# STM32F40x register map
File version: 1.5
Registers are 32-bit, read-write, reset 0x0 unless marked. A register's access mark holds for its fields unless they carry their own. Offsets are from the block's base; [hi:lo] are bit positions.

## TIM6（定时器6(基本定时器)） — 基本定时器：计数/比较/PWM/输入捕获 | Basic timers
Base 0x40001000
Same registers: TIM7（定时器7(基本定时器)） 0x40001400
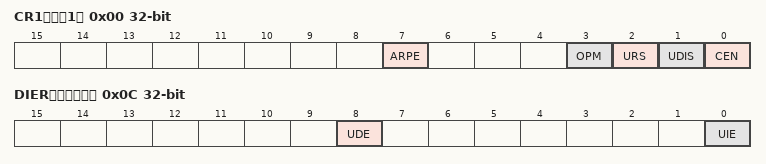
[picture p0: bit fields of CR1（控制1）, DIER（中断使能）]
0x00 CR1（控制1） — 控制1：计数器使能/对齐/分频 | control register 1
  [7] ARPE — Auto-reload preload enable
  [3] OPM — One-pulse mode
  [2] URS — Update request source
  [1] UDIS — Update disable
  [0] CEN — Counter enable
0x04 CR2（控制2） — 控制2：主模式选择 | control register 2
  [6:4] MMS — Master mode selection
0x0C DIER（中断使能） — DMA/中断使能 | DMA/Interrupt enable register
  [8] UDE — Update DMA request enable
  [0] UIE — Update interrupt enable
0x10 SR（状态） — 状态：更新中断标志 | status register
  [0] UIF — Update interrupt flag
0x14 EGR（事件生成） wo — 事件生成 | event generation register
  [0] UG — Update generation
0x24 CNT（计数器） — 当前计数值 | counter
  [15:0] CNT — Low counter value
0x28 PSC（预分频） — 预分频 | prescaler
  [15:0] PSC — Prescaler value
0x2C ARR（自动重装） — 自动重装载值 | auto-reload register
  [15:0] ARR — Low Auto-reload value

## Ethernet_MAC（以太网_MAC_媒体访问控制） — 以太网 MAC 媒体访问控制（best-effort） | Ethernet: media access control (MAC)
Base 0x40028000
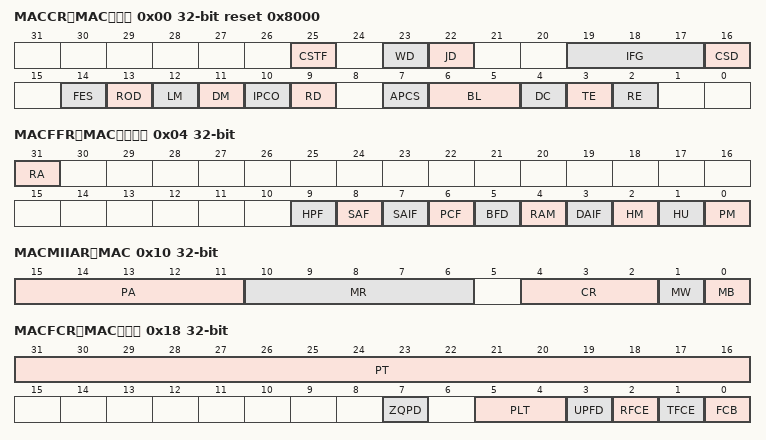
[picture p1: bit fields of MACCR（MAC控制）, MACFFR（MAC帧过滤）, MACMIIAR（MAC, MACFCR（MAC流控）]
0x00 MACCR（MAC控制） reset 0x8000 — MAC 控制 | Ethernet MAC configuration register
  [25] CSTF, [23] WD, [22] JD, [19:17] IFG, [16] CSD, [14] FES, [13] ROD, [12] LM, [11] DM, [10] IPCO, [9] RD, [7] APCS, [6:5] BL, [4] DC, [3] TE, [2] RE
0x04 MACFFR（MAC帧过滤） — MAC 帧过滤 | Ethernet MAC frame filter register
  [31] RA, [9] HPF, [8] SAF, [7] SAIF, [6] PCF, [5] BFD, [4] RAM, [3] DAIF, [2] HM, [1] HU, [0] PM
0x08 MACHTHR（MAC哈希高） — MAC 哈希表高 | Ethernet MAC hash table high register
  [31:0] HTH
0x0C MACHTLR（MAC哈希低） — MAC 哈希表低 | Ethernet MAC hash table low register
  [31:0] HTL
0x10 MACMIIAR（MAC MII地址） — MAC MII 地址 | Ethernet MAC MII address register
  [15:11] PA, [10:6] MR, [4:2] CR, [1] MW, [0] MB
0x14 MACMIIDR（MAC MII数据） — MAC MII 数据 | Ethernet MAC MII data register
  [15:0] TD
0x18 MACFCR（MAC流控） — MAC 流控 | Ethernet MAC flow control register
  [31:16] PT, [7] ZQPD, [5:4] PLT, [3] UPFD, [2] RFCE, [1] TFCE, [0] FCB
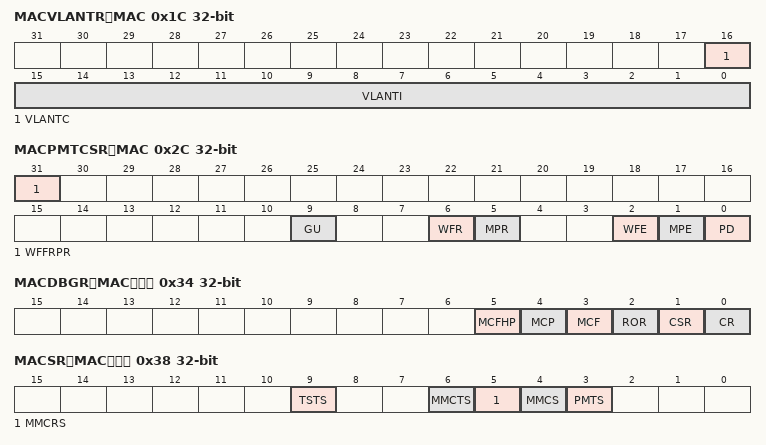
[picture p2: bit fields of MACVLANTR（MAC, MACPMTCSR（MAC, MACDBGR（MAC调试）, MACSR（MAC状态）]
0x1C MACVLANTR（MAC VLAN标签） — MAC VLAN 标签 | Ethernet MAC VLAN tag register
  [16] VLANTC, [15:0] VLANTI
0x2C MACPMTCSR（MAC 电源管理） — MAC 电源管理控制 | Ethernet MAC PMT control and status register
  [31] WFFRPR, [9] GU, [6] WFR, [5] MPR, [2] WFE, [1] MPE, [0] PD
0x34 MACDBGR（MAC调试） ro — MAC 调试 | Ethernet MAC debug register
  [5] MCFHP, [4] MCP, [3] MCF, [2] ROR, [1] CSR, [0] CR
0x38 MACSR（MAC状态） access per field — MAC 状态 | Ethernet MAC interrupt status register
  [9] TSTS rw, [6] MMCTS ro, [5] MMCRS ro, [4] MMCS ro, [3] PMTS ro
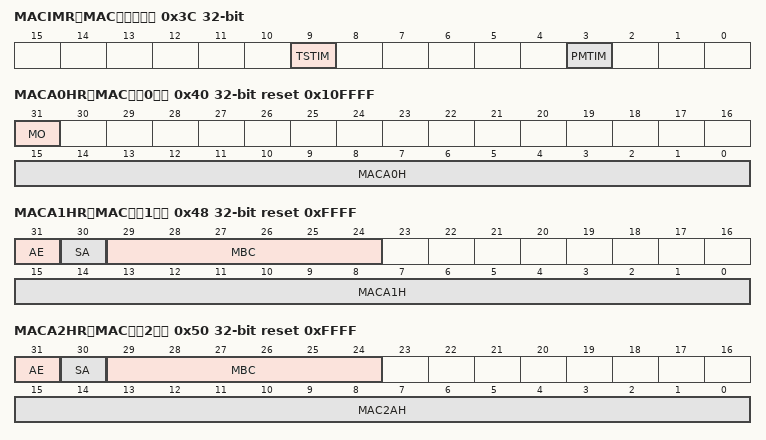
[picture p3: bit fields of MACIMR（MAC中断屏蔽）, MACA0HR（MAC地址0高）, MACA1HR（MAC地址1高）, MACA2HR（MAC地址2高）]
0x3C MACIMR（MAC中断屏蔽） — MAC 中断屏蔽 | Ethernet MAC interrupt mask register
  [9] TSTIM, [3] PMTIM
0x40 MACA0HR（MAC地址0高） access per field reset 0x10FFFF — MAC 地址 0 高 | Ethernet MAC address 0 high register
  [31] MO ro — Always 1
  [15:0] MACA0H rw — MAC address0 high
0x44 MACA0LR（MAC地址0低） reset 0xFFFFFFFF — MAC 地址 0 低 | Ethernet MAC address 0 low register
  [31:0] MACA0L — 0
0x48 MACA1HR（MAC地址1高） reset 0xFFFF — MAC 地址 1 高（best-effort） | Ethernet MAC address 1 high register
  [31] AE, [30] SA, [29:24] MBC, [15:0] MACA1H
0x4C MACA1LR（MAC地址1低） reset 0xFFFFFFFF — MAC 地址 1 低（best-effort） | Ethernet MAC address1 low register
  [31:0] MACA1LR
0x50 MACA2HR（MAC地址2高） reset 0xFFFF — MAC 地址 2 高（best-effort） | Ethernet MAC address 2 high register
  [31] AE, [30] SA, [29:24] MBC, [15:0] MAC2AH
0x54 MACA2LR（MAC地址2低） reset 0xFFFFFFFF — MAC 地址 2 低（best-effort） | Ethernet MAC address 2 low register
  [30:0] MACA2L
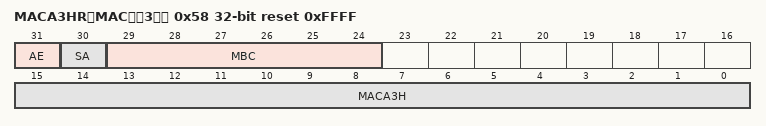
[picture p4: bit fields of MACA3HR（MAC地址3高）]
0x58 MACA3HR（MAC地址3高） reset 0xFFFF — MAC 地址 3 高（best-effort） | Ethernet MAC address 3 high register
  [31] AE, [30] SA, [29:24] MBC, [15:0] MACA3H
0x5C MACA3LR（MAC地址3低） reset 0xFFFFFFFF — MAC 地址 3 低（best-effort） | Ethernet MAC address 3 low register
  [31:0] MBCA3L

## Ethernet_MMC（以太网_MMC_管理计数器） — 以太网 MMC 管理计数器（best-effort） | Ethernet: MAC management counters
Base 0x40028100
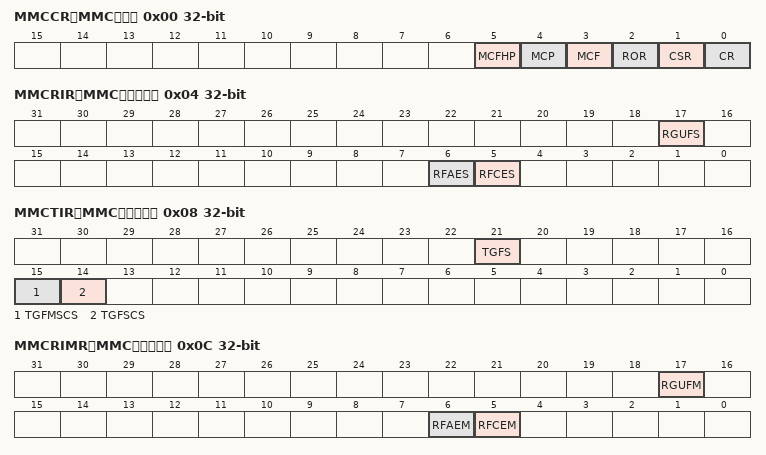
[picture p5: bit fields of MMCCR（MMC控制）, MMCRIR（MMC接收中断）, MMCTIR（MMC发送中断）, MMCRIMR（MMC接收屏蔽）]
0x00 MMCCR（MMC控制） — MMC 控制 | Ethernet MMC control register
  [5] MCFHP, [4] MCP, [3] MCF, [2] ROR, [1] CSR, [0] CR
0x04 MMCRIR（MMC接收中断） — MMC 接收中断 | Ethernet MMC receive interrupt register
  [17] RGUFS, [6] RFAES, [5] RFCES
0x08 MMCTIR（MMC发送中断） ro — MMC 发送中断 | Ethernet MMC transmit interrupt register
  [21] TGFS, [15] TGFMSCS, [14] TGFSCS
0x0C MMCRIMR（MMC接收屏蔽） — MMC 接收中断屏蔽 | Ethernet MMC receive interrupt mask register
  [17] RGUFM, [6] RFAEM, [5] RFCEM
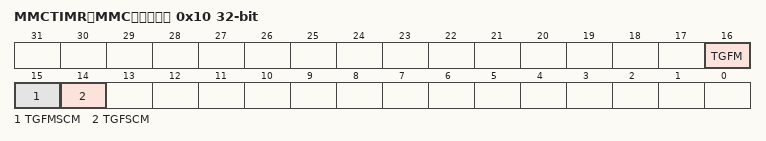
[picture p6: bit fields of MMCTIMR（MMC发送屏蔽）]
0x10 MMCTIMR（MMC发送屏蔽） — MMC 发送中断屏蔽 | Ethernet MMC transmit interrupt mask register
  [16] TGFM, [15] TGFMSCM, [14] TGFSCM
0x4C MMCTGFSCCR（MMC统计） ro — MMC 统计寄存器 MMCTGFSCCR（best-effort） | Ethernet MMC transmitted good frames after a single collision counter
  [31:0] TGFSCC
0x50 MMCTGFMSCCR（MMC发送单碰撞） ro — MMC 发送好帧单碰撞计数 | Ethernet MMC transmitted good frames after more than a single collision
  [31:0] TGFMSCC
0x68 MMCTGFCR（MMC发送好帧） ro — MMC 发送好帧计数 | Ethernet MMC transmitted good frames counter register
  [31:0] TGFC — HTL
0x94 MMCRFCECR（MMC接收CRC错） ro — MMC 接收 CRC 错误计数 | Ethernet MMC received frames with CRC error counter register
  [31:0] RFCFC
0x98 MMCRFAECR（MMC接收对齐错） ro — MMC 接收对齐错误计数 | Ethernet MMC received frames with alignment error counter register
  [31:0] RFAEC
0xC4 MMCRGUFCR（MMC接收单播） ro — MMC 接收单播帧计数 | MMC received good unicast frames counter register
  [31:0] RGUFC
